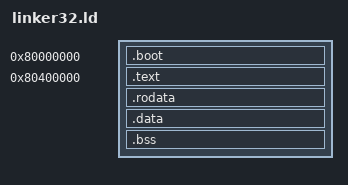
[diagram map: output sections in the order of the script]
/* Copy from bbl-ucore : https://ring00.github.io/bbl-ucore      */

/* Simple linker script for the ucore kernel.
   See the GNU ld 'info' manual ("info ld") to learn the syntax. */

OUTPUT_ARCH(riscv)
ENTRY(_start)

BASE_ADDRESS = 0x80400000;

SECTIONS
{
    . = 0x80000000;
    .boot : {
        KEEP(*(.text.boot))
    }

    /* Load the kernel at this address: "." means the current address */
    . = BASE_ADDRESS;
    start = .;

    .text : {
        *(.text.entry)
        *(.text .text.*)
    }

    .rodata : {
        srodata = .;
        *(.rodata .rodata.*)
        . = ALIGN(4K);
        erodata = .;
    }

    .data : {
        sdata = .;
        *(.data .data.*)
        *(.sdata .sdata.*)
        edata = .;
    }


    .bss : {
        sbss = .;
        *(.bss .bss.*)
        *(.sbss .sbss.*)
        ebss = .;
    }

    PROVIDE(end = .);
}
